# iqn_ail register map
Vendor: Texas Instruments
Registers are 32-bit, read-only, no defined reset value unless marked. A register's access mark holds for its fields unless they carry their own. Offsets are as the file gives them; [hi:lo] are bit positions; lines under a group give offsets from that group; {n}, {i} and the like mark numbered series; 'fields as' and 'values as' point back to an identical list.

## IQN_AIL (part 2 of 5)
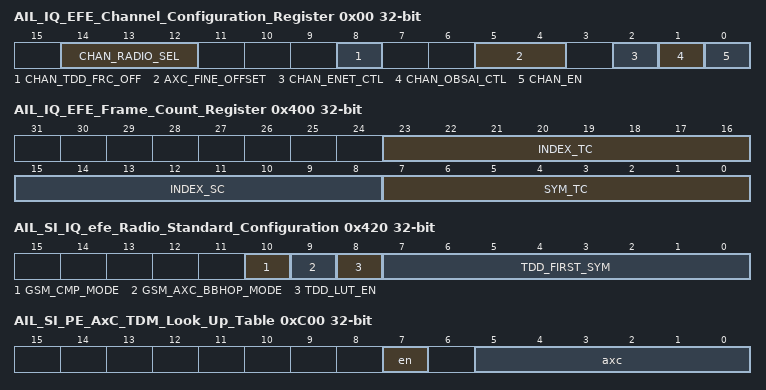
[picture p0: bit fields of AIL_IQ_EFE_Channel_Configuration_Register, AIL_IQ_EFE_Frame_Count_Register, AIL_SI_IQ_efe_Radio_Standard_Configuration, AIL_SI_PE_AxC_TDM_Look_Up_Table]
0x00 AIL_IQ_EFE_Channel_Configuration_Register rw — (1 of 1, stride 0)
  [14:12] CHAN_RADIO_SEL — Assigns each channel to one of eight radio standard groups. i.e. radio standard 0 may be LTE 20MHz
  [8] CHAN_TDD_FRC_OFF — Alternate TDD mode for controlling TDD also used for GSM Base Band Hopping. APP SW controls updates this bit each symbol of time to control whether the next symbol will be TDD OFF. TDD OFF channels generate no Ingress DMA traffic and expect no Egress DMA
  [5:4] AXC_FINE_OFFSET — Selects sample in a QSD that would be the start of the frame.
  [2] CHAN_ENET_CTL — Selects ENET mode when high and non-ENET mode when low.
  [1] CHAN_OBSAI_CTL — Selects when OBSAI CTL traffic is being passed on an SI_IQ channel (CPRI CTL traffic is passed on the SI_CTL). CTL traffic is on-demand while AxC traffic is streaming. Prevents SI_IQ from activating the starvation handling circuits when packet traffic is
  [0] CHAN_EN — Enable channel
0x200 AIL_IQ_EFE_Configuration_Register rw — (1 of 1, stride 0)
  [0] LOOPBACK_EN — (TI use Only) 0x1: Ingress data from ICC is looped back to Egress data to ICC. DMA traffic is unused. (i.e. for purpose of early DFE only testing)
0x240 AIL_IQ_EFE_Global_Enable_Set_Reg wo — (1 of 1, stride 0)
  [31:0] DONT_CARE — A write of any value to this register which sets (enables) global enable
0x244 AIL_IQ_EFE_Global_Enable_Clear_Reg wo — (1 of 1, stride 0)
  [31:0] DONT_CARE — A write of any value to this register which clears (enables) global enable
0x248 AIL_IQ_EFE_Global_Enable_Status — (1 of 1, stride 0)
  [0] ENABLE — 0x1: efe_ON 0x0:efe_OFF
0x260 AIL_IQ_EFE_Channel_ON_Status_Reg — (1 of 1, stride 0)
  [31:0] CHAN_ON — 0x1: CHAN_ON 0x0:CHAN_OFF
0x280 AIL_IQ_EFE_IN_Packet_Status_Registers — (1 of 1, stride 0)
  [31:0] IN_PKT — 0x1: IN_PKT 0x0:OUT_PKT
0x2A0 AIL_IQ_EFE_DMA_SYNC_Status_Registers — (1 of 1, stride 0)
  [31:0] DMA_SYNC — 0x1: DMA synchronized to radio timing for this channel 0x0:DMA not synchronized to radio timing for this channel. Channel is in in re-sync mode.
0x400 AIL_IQ_EFE_Frame_Count_Register rw — (1 of 1, stride 0)
  [23:16] INDEX_TC — Radio Framing Counter. Index Counter Terminal Count. Index counter terminal count which is the last value of the Index Counter before it wraps. For simple use case, program same as frm_sym_tc.
  [15:8] INDEX_SC — Radio Framing Counter. Index Counter Starting Location. Starting location of the Sample Terminal Count LUT loaded into the Index Counter when it first starts and each time it wraps. Depending on the radio standard, the index will wrap once per radio frame
  [7:0] SYM_TC — Radio Framing Counter. Symbol Count. Number of symbols per frame programmed as a terminal count.
0x420 AIL_SI_IQ_efe_Radio_Standard_Configuration rw — (1 of 1, stride 0)
  [10] GSM_CMP_MODE — Enables GSM Compressed mode
  [9] GSM_AXC_BBHOP_MODE — Enables Base-band Hopping mode
  [8] TDD_LUT_EN — Enable TDD
  [7:0] TDD_FIRST_SYM — Selects first symbol to start TDD
{0x440+0x20*i} AIL_IQ_efe_Radio_Standard_{i}_TDD_ENABLE_LUT rw (i=0..7) — (1 of 1, stride 0)
  [31:0] TDD_EN — enables/disables DMA of whole symbols (PktDMA packets). Program as 0xffff for most applications.
0x600 AIL_IQ_EFE_Channel_AXC_Offset_Reg rw — (1 of 64, stride 4)
  [24:0] AXC_OFFSET — AxC-by-AxC delay control. Allows different timing alignments for each AxC. DIO, AID applicactions this is a 4 sample offset relatvie to the group or TDM of AxC. AIL CPRI, this is a sample offset relative to the CPRI AxC Group. AIL OBSAI, this is a Radio
0x800 AIL_IQ_EFE_AxC_Framing_Sample_Terminal_Count rw — (1 of 256, stride 4)
  [17:0] SAMP_TC — Radio Framing Counter. Number of samples (4 Bytes) per radio symbol programmed as a terminal count
0xC00 AIL_SI_PE_AxC_TDM_Look_Up_Table rw — (1 of 256, stride 4)
  [7] en — Enables each entry. Disabled entries will result in zeroed CPRI containers. Main use of this disable, so APP SW is not required to maintain unique AxC value for unused containers.
  [5:0] axc — List of AxC indexes giving TDM AxC order over CPRI or OBSAI link
0x1000 AIL_SI_PE_PHY_Configuration_Register rw — (1 of 1, stride 0)
  [0] phy_en — SI Egress AIL scheduler, PHY FSM is enabled to turn ON, will turn on next PE_FB from uAT
0x1004 AIL_SI_PE_PHY_Status_Register — (1 of 1, stride 0)
  [0] phy_on — SI Egress AIL scheduler, active high, indicating that the PE PHY is in ON state. PE PHY will only turn ON/OFF on PE_FB boundaries.
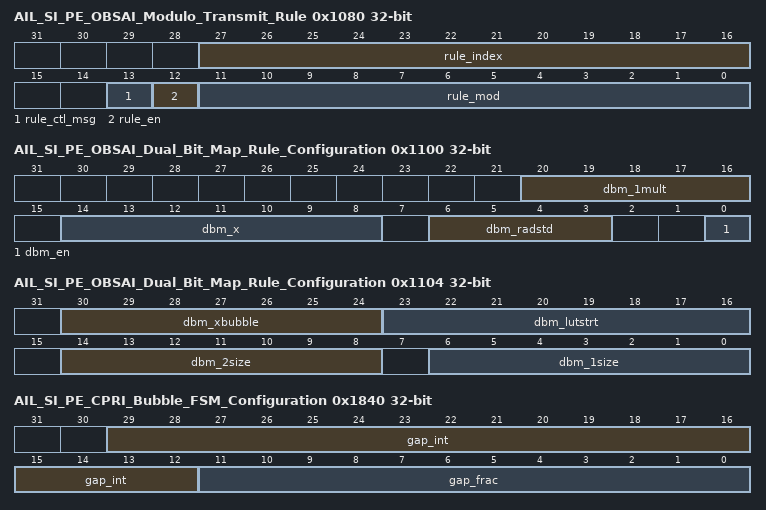
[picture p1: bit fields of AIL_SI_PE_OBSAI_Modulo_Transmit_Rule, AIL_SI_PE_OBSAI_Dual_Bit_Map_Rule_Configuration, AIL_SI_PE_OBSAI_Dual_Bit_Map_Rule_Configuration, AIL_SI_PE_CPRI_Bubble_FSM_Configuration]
0x1080 AIL_SI_PE_OBSAI_Modulo_Transmit_Rule rw — (1 of 1, stride 0)
  [27:16] rule_index — Index. Transmission Rule. Index indicates at which count the rule will fire.
  [13] rule_ctl_msg — 1: Module Rule oppeations on OBSAI control messages 0: AxC messages
  [12] rule_en — Transmission Rule Enable.
  [11:0] rule_mod — Modulo Terminal count of the rule counter. Dictates the period of the rule. Terminal count is the OBSAI Module minus 1.
0x1100 AIL_SI_PE_OBSAI_Dual_Bit_Map_Rule_Configuration rw — (1 of 32, stride 8)
  [20:16] dbm_1mult — DBMF repititions of map1
  [14:8] dbm_x — DBMF max number of supported channels
  [6:3] dbm_radstd — OBSAI only: Radio Standard 0-7 corresponding to the given rule. Controls which RADT to be used flr AxC_Offset comparison. Highly recommended to use a single rule per radio standard to simplify AxC_Offset calculations
  [0] dbm_en — DBMF Enable: When disabled and MOD rule fires, first AxC LUT entry is used and other DBM programming is disregarded
0x1104 AIL_SI_PE_OBSAI_Dual_Bit_Map_Rule_Configuration rw — (1 of 32, stride 8)
  [30:24] dbm_xbubble — Normally programmed to 0 corresponding to 1 bubble when a bubble is indicated by Map1 or Map2 pattern. (Future Proof) feature allows a burst of bubbles to be inserted. Burst length indicated by this MMR
  [23:16] dbm_lutstrt — DBMF Starting address for chan TDM LUT pe_rule_chanlut. LUT is shared by all 32 DBM rules. Starting address indicates where pattern for this rule starts
  [14:8] dbm_2size — DBMF number of bits of bit map2 to use.
  [6:0] dbm_1size — DBMF number of bits of bit map1 to use.
0x1400 AIL_SI_PE_OBSAI_Dual_Bit_Map_Rule__Bit_Map rw — (1 of 256, stride 4)
  [31:0] dbm_bit_map — DBMF bit map 1,2
0x1800 AIL_SI_PE_CPRI_Configuration_Register rw — (1 of 1, stride 0)
  [6:0] axc_cont_tc — CPRI,indicating how many CPRI AxC containers are supported within each basic frame. Value must be consistently programmed with AIL_PHY_Egress programmed values or erroneous operation will result.. Programmed values 0-to-63 correspond to length 1-to-64.
0x1820 AIL_SI_PE_CPRI_Bubble_FSM_Configuration rw — (1 of 1, stride 0)
  [31:14] knc — (K x Nc) total number of containers per AxC Container Block. 0=one
0x1840 AIL_SI_PE_CPRI_Bubble_FSM_Configuration rw — (1 of 1, stride 0)
  [29:12] gap_int — fsm-by-fsm, integer number of containers between bubbles. 0=one which indicates every clock would be a bubble, assuming bub_gap_frac is also zero. Algorithm rewinds at the beginning of each AxC Container Block
  [11:0] gap_frac — fsm-by-fsm, fractional number of containers between bubbles. 0=zero. Value is accumulated every bubble, in this way, a non-zero fraction eventually accumulates into the integer field
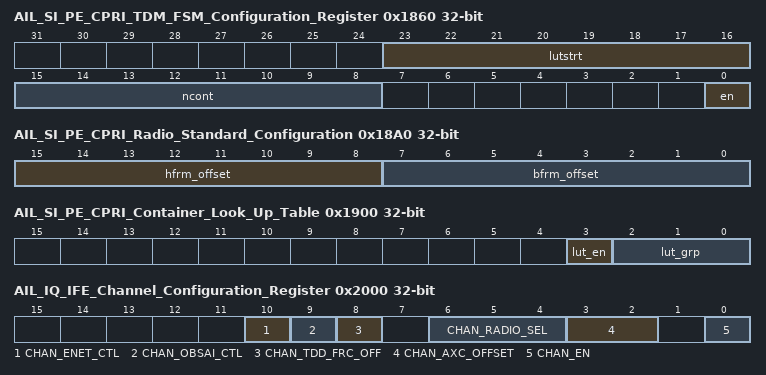
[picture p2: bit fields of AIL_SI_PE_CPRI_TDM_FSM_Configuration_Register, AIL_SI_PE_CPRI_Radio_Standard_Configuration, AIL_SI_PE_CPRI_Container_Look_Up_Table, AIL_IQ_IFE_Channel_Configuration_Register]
0x1860 AIL_SI_PE_CPRI_TDM_FSM_Configuration_Register rw — (1 of 1, stride 0)
  [23:16] lutstrt — first AxC_LUT entry for this fsm. Effectively controls how the table is shared betweeen up to 8 groups or fsm
  [15:8] ncont — number of AxC_LUT entries for this FSM (For each LTE20, 8 sequential entries within AxC_LUT)
  [0] en — FIXME REMOVE THIS MMR FIELD... REDUNDANT WITH pe_cpri_radstd_cfg.en
0x1880 AIL_SI_PE_CPRI_Radio_Standard_Configuration rw — (1 of 1, stride 0)
  [0] en — Enable bit for the corresponding radio standard First enabled radstd must be radstd0, next radstd1, ...
0x18A0 AIL_SI_PE_CPRI_Radio_Standard_Configuration rw — (1 of 1, stride 0)
  [15:8] hfrm_offset — Hyper Frame Index of Radio Standard Offset
  [7:0] bfrm_offset — Basic Frame Index of Radio Standard Offset
0x18C0 AIL_SI_PE_CPRI_Radio_Standard_Configuration rw — (1 of 1, stride 0)
  [17:0] bfrm_num — Number of Basic Frames in a Radio Standard
0x18E0 AIL_SI_PE_CPRI_Radio_Standard_Status_Register — (1 of 1, stride 0)
  [0] on — 0x1: RADSTD_ON 0x0:RADSTD_OFF
0x1900 AIL_SI_PE_CPRI_Container_Look_Up_Table rw — (1 of 1, stride 0)
  [3] lut_en — Enable or Disable of each contain, even if disabled, CONT_LUT_GRP must be programmed correctly
  [2:0] lut_grp — Group (radio standard) which container belongs to, 0-to-7. When programming must exactly match the AIL_PHY_CO programmed pperation.
0x2000 AIL_IQ_IFE_Channel_Configuration_Register rw — (1 of 1, stride 0)
  [10] CHAN_ENET_CTL — Selects between OBSAI ENET when high or OBSAI NON_ENET when low. Only valid when CHAN_OBSAI_CTL is set
  [9] CHAN_OBSAI_CTL — Selects between OBSAI when high or CPRI when low.
  [8] CHAN_TDD_FRC_OFF — Forces a channel into the TDD OFF state on the next symbol after it is set to a 1 regardless of the TDD configuration of the radio standard variant the channel is assigned to.
  [6:4] CHAN_RADIO_SEL — Radio Standard Select
  [3:2] CHAN_AXC_OFFSET — AxC Offset
  [0] CHAN_EN — Enable channel
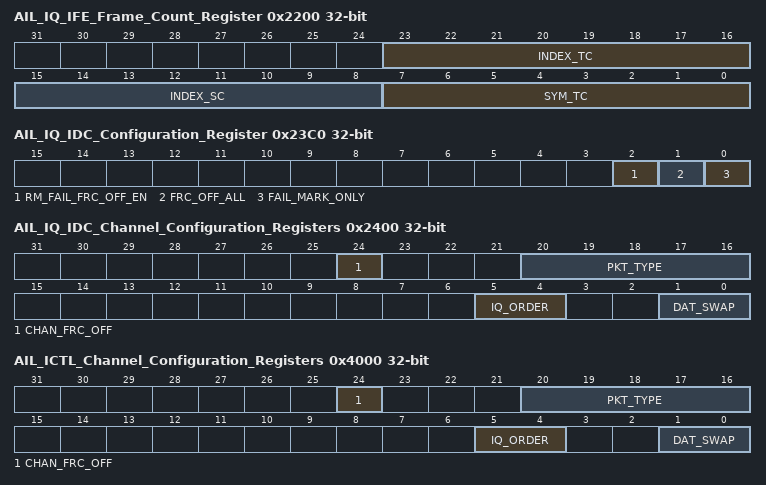
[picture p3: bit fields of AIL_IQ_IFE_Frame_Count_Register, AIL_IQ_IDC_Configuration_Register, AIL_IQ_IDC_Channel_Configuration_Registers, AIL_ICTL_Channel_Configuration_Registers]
0x2200 AIL_IQ_IFE_Frame_Count_Register rw — (1 of 1, stride 0)
  [23:16] INDEX_TC — Radio Framing Counter. Index Counter Terminal Count. Index counter terminal count which is the last value of the Index Counter before it wraps. For simple use case, program same as frm_sym_tc.
  [15:8] INDEX_SC — Radio Framing Counter. Index Counter Starting Location. Starting location of the Sample Terminal Count LUT loaded into the Index Counter when it first starts and each time it wraps.
  [7:0] SYM_TC — Radio Framing Counter. Symbol Count. Number of symbols per frame programmed as a terminal count.
0x2220 AIL_IQ_IFE_Radio_Standard_Configuration rw — (1 of 1, stride 0)
  [0] TDD_LUT_EN — Enable TDD
{0x2240+0x20*i} AIL_IQ_IFE_Radio_Standard_{i}_TDD_ENABLE_LUT rw (i=0..7) — (1 of 1, stride 0)
  fields as AIL_IQ_efe_Radio_Standard_0_TDD_ENABLE_LUT
0x2340 AIL_IQ_IFE_Global_Enable_Set_Reg wo — (1 of 1, stride 0)
  fields as AIL_IQ_EFE_Global_Enable_Set_Reg
0x2344 AIL_IQ_IFE_Global_Enable_Clear_Reg wo — (1 of 1, stride 0)
  fields as AIL_IQ_EFE_Global_Enable_Clear_Reg
0x2348 AIL_IQ_IFE_Global_Enable_Status — (1 of 1, stride 0)
  [0] ENABLE — 0x1: ife_ON 0x0:ife_OFF
0x2350 AIL_IQ_IFE_Channel_ON_Status_Reg — (1 of 1, stride 0)
  [31:0] CHAN_ON — 0x1: CHAN_ON 0x0:CHAN_OFF
0x2360 AIL_IQ_IFE_IN_Packet_Status_Registers — (1 of 1, stride 0)
  [31:0] IN_PKT — 0x1: IN_PKT 0x0:OUT_PKT
0x2384 AIL_IQ_IDC_Status_Register — (1 of 1, stride 0)
  [0] EMPTY — Empty indicator for both the PSI Staging FIFO and the CDC FIFO
0x2390 AIL_IQ_IDC_In_Packet_Status_Register — (1 of 1, stride 0)
  [31:0] INPKT — Per-channel in packet status bits where a 0 indicates that the channel is not actively processing a packet and a 1 indicates that it is actively processing a packet. The inpkt to channel assignment is such that inpkt\[0\] is associated with channel 0 and
0x23C0 AIL_IQ_IDC_Configuration_Register rw — (1 of 1, stride 0)
  [2] RM_FAIL_FRC_OFF_EN — Forces off all Ingress channels without waiting for an end of symbol or time slot if there is an RM failure. All open packets are automatically closed by creating an EOP for each open packet
  [1] FRC_OFF_ALL — Forces off all Ingress channels without waiting for an end of symbol or time slot. All open packets are automatically closed by creating an EOP for each open packet
  [0] FAIL_MARK_ONLY — Controls how the IDC handles packet errors detected by IFE
0x2400 AIL_IQ_IDC_Channel_Configuration_Registers rw — (1 of 1, stride 0)
  [24] CHAN_FRC_OFF — Forces off all channel without waiting for an end of symbol or time slot. If channel has an open packet it is automatically closed by creating an EOP
  [20:16] PKT_TYPE — Programmable packet type that is inserted into pkt_type field of PKTDMA Info Word 0.
  [5:4] IQ_ORDER — IQ swapping control.
  [1:0] DAT_SWAP — Byte swapping control.
0x2800 AIL_IQ_IFE_AxC_Framing_Sample_Terminal_Count rw — (1 of 256, stride 4)
  fields as AIL_IQ_EFE_AxC_Framing_Sample_Terminal_Count
0x3000 AIL_ECTL_Global_Enable_Set_Reg wo — (1 of 1, stride 0)
  fields as AIL_IQ_EFE_Global_Enable_Set_Reg
0x3004 AIL_ECTL_Global_Enable_Clear_Reg wo — (1 of 1, stride 0)
  fields as AIL_IQ_EFE_Global_Enable_Clear_Reg
0x3008 AIL_ECTL_Global_Enable_Status — (1 of 1, stride 0)
  [0] ENABLE — 0x1: ectl_ON 0x0:ectl_OFF
0x3100 AIL_ECTL_Channel_ON_Status_Reg — (1 of 1, stride 0)
  [3:0] CHAN_ON — 0x1: CHAN_ON 0x0:CHAN_OFF
0x3140 AIL_ECTL_In_Packet_Status_Register — (1 of 1, stride 0)
  [3:0] IN_PKT — Per-channel in packet status bits where a 0 indicates that the channel is not actively processing a packet and a 1 indicates that it is actively processing a packet. The inpkt to channel assignment is such that inpkt\[0\] is associated with channel 0 and
0x3200 AIL_ECTL_Channel_Enable_Configuration_Register rw — (1 of 1, stride 0)
  [0] CHAN_EN — Enable channel
0x3400 AIL_ECTL_DB_Threshold_Register rw — (1 of 1, stride 0)
  [4:0] CHANNEL — Data Buffer Threshold before indicating data available. Per channel
0x4000 AIL_ICTL_Channel_Configuration_Registers rw — (1 of 1, stride 0)
  [24] CHAN_FRC_OFF — Forces off all channel without waiting for an EOP. If channel has an open packet it is automatically closed by creating an EOP
  [20:16] PKT_TYPE — Programmable packet type that is inserted into pkt_type field of PKTDMA Info Word 0.
  [5:4] IQ_ORDER — IQ swapping control.
  [1:0] DAT_SWAP — Byte swapping control.
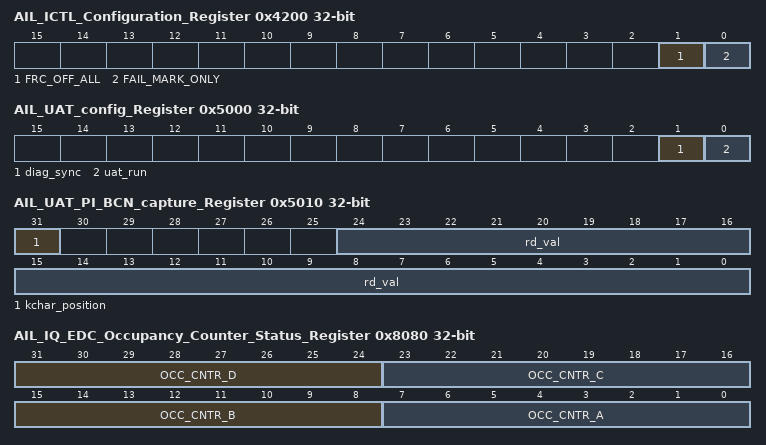
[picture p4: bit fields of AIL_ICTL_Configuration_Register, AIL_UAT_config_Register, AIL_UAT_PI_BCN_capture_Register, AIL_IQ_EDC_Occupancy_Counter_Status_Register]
0x4200 AIL_ICTL_Configuration_Register rw — (1 of 1, stride 0)
  [1] FRC_OFF_ALL — Forces off all Ingress channels without waiting for an EOP. All open packets are automatically closed by creating an EOP for each open packet
  [0] FAIL_MARK_ONLY — Controls how the ICTL handles packet errors detected by ICTL
0x4204 AIL_ICTL_Status_Register — (1 of 1, stride 0)
  fields as AIL_IQ_IDC_Status_Register
0x4210 AIL_ICTL_In_Packet_Status_Register — (1 of 1, stride 0)
  fields as AIL_ECTL_In_Packet_Status_Register
0x4280 AIL_ICTL_Global_Enable_Set_Reg wo — (1 of 1, stride 0)
  fields as AIL_IQ_EFE_Global_Enable_Set_Reg
0x4284 AIL_ICTL_Global_Enable_Clear_Reg wo — (1 of 1, stride 0)
  fields as AIL_IQ_EFE_Global_Enable_Clear_Reg
0x4288 AIL_ICTL_Global_Enable_Status — (1 of 1, stride 0)
  [0] ENABLE — 0x1: ictl_ON 0x0:ictl_OFF
0x42A0 AIL_ICTL_Channel_ON_Status_Reg — (1 of 1, stride 0)
  [3:0] CHAN_ON — 0x1: CHAN_ON 0x0:CHAN_OFF
0x4400 AIL_ICTL_Channel_Enable_Configuration_Register rw — (1 of 1, stride 0)
  [0] CHAN_EN — Enable channel
0x5000 AIL_UAT_config_Register rw — (1 of 1, stride 0)
  [1] diag_sync — diag_sync = 1 starts the BCN and RAD counters if uat_run is set and an AT sync is received. This is only used in simulation and for diagnostics
  [0] uat_run — UAT run starts the BCN and RAD counters free running
0x5004 AIL_UAT_BCN_terminal_count_Register rw — (1 of 1, stride 0)
  [24:0] val — UAT BCN terminal count. BCN counts from zero to this limit and wraps to zero. Program as 2,457,599 for sys_clk=245.76MHz and 3,071,999 for sys_clk=307.2MHz
0x5008 AIL_UAT_BCN_offset_Register rw — (1 of 1, stride 0)
  [24:0] val — Offset correction to the raw uAT BCN counter. Used to correct the alignment of the local uAT BCN to the master AT2 BCN. BCN is initially randomly started. SW uses uat_sync_bcn_capture_sts rd_val to calculate offset correction factor. This correction
0x500C AIL_UAT_SYNC_BCN_capture_Register — (1 of 1, stride 0)
  [24:0] rd_val — uAT raw BCN value captured each frame boundary of AT2 master BCN. Used to calculate uAT BCN offset value for the purpose of aligning uAT to AT2 BCN.
0x5010 AIL_UAT_PI_BCN_capture_Register — (1 of 1, stride 0)
  [31] kchar_position — (AIL use only) uAT pi K character position. Captures the k character position when the AIL_PHY_RM detects a CPRI or OBSAI PHY frame boundary (SOF). 0 means that the kchar for SOF was detected on the lower byte of the SERDES receive data, 1 means upper
  [24:0] rd_val — (AIL use only) uAT pi BCN capture. Captures the BCN timer value when the AIL_PHY_RM detects a CPRI or OBSAI PHY frame boundary (SOF).
0x5014 AIL_UAT_PIMAX_CFG rw — (1 of 1, stride 0)
  [24:0] val — (AIL use only) PI max window. One of two values which indicate the legal range for OBSAI or CPRI PHY SOF. When an SOF is recieved outside this window, and error is indicated (EE)
0x5018 AIL_UAT_PIMIN_CFG rw — (1 of 1, stride 0)
  [24:0] val — (AIL use only) PI min window. One of two values which indicate the legal range for OBSAI or CPRI PHY SOF. When an SOF is recieved outside this window, and error is indicated (EE)
0x501C AIL_UAT_RP301_BCN_capture_Register — (1 of 1, stride 0)
  [24:0] rd_val — (AIL use only) uAT RP3-01 BCN capture. Captures the BCN offset count when the phy detects an OBSAI RP3-01 strobe from the AIL_PD.
0x5020 AIL_UAT_TM_Frame_configuration_Register wo — (1 of 1, stride 0)
  [11:0] wr_val — (AIL CPRI use only) uAT CPRI BFN count value (Write only). SW overwrite current value. uAT will increment every TM_FRM_STB
0x5024 AIL_UAT_TM_Frame_status_Register — (1 of 1, stride 0)
  [11:0] rd_val — (AIL CPRI use only) uAT CPRI BFN count value (Read only). Initially set by uat_tm_bfn_cfg, increments every CPRI PHY frame.
0x5028 AIL_UAT_RT_FB_Register rw — (1 of 1, stride 0)
  [24:0] val — (AIL use only) uAT BCN compare value which cause RT_STB to fire. Used for Egress PHY timing. RT_STB is the latest moment that RT will wait for PE and CI SOF contribution before progressing without either input.
0x502C AIL_UAT_pe_FB_Register rw — (1 of 1, stride 0)
  [24:0] val — (AIL use only) uAT BCN compare value which cause PE_STB to fire. Used for Egress PROTO, PHY timing. PE_STB is the exact time which PE will start building the PHY protocol. It also represents the latest timing for incoming DMA data to contribute to the
0x5030 AIL_UAT_tm_FB_Register rw — (1 of 1, stride 0)
  [24:0] val — (AIL use only) uAT BCN compare value which cause RT_STB to fire. Used for Egress PHY timing. TM_STB (OBSAI Delta) is the precise time at which TM exports the CPRI or OBSAI PHY SOF
0x5080 AIL_UAT_RADT_terminal_count_Register rw — (1 of 8, stride 16)
  [24:0] val — UAT RADT terminal count. (i.e. 2,457,599 for WCDMA with sys_clk=245.76MHz)
0x5084 AIL_UAT_RADT_offset_Register rw — (1 of 8, stride 16)
  [24:0] val — UAT RADT offset. Value which is added to the raw RADT as a timing correction. RadT is initially randomly started, SW uses radt_capture value to calculate offset correction factor. This correction factor will be Frame size
0x5088 AIL_UAT_SYNC_RADT_capture_Register — (1 of 8, stride 16)
  [24:0] rd_val — UAT RADT sync capture captures the offset RADT count when a uat_mst_slv_sync from the AT occurs. Used by SW to determine correct RADT offset to apply.
0x5100 AIL_UAT_RADT_terminal_count_Register rw — (1 of 8, stride 16)
  fields as AIL_UAT_RADT_terminal_count_Register
0x5104 AIL_UAT_RADT_offset_Register rw — (1 of 8, stride 16)
  fields as AIL_UAT_RADT_offset_Register
0x5108 AIL_UAT_SYNC_RADT_capture_Register — (1 of 8, stride 16)
  fields as AIL_UAT_SYNC_RADT_capture_Register
0x5200 AIL_UAT_RADT_event_compare_Register rw — (1 of 22, stride 8)
  [24:0] val — UAT RADT event compare per RADT. When compare value equals RADT count, frame rate event is generated. Also periodic event (i.e. 4SAMP) is started. The 0 to 7 are for si egress, 8 to 15 for si ingress, 16 to 18 for dio egress, 19 to 21 for dio ingress
0x5204 AIL_UAT_RADT_event_clock_count_tc_Register rw — (1 of 22, stride 8)
  [15:0] val — UAT RADT event clock counter terminal count controls spacing of the periodic strobe (i.e. 4SAMP). Once the uat_evt_radt_cmp_cfg equals the RADT, the period strobe will fire and re-fire every time a clock counter reaches this terminal count. The The 0 to 7
0x8000 AIL_IQ_EDC_Configuration_Register rw — (1 of 1, stride 0)
  [0] PSI_ERR_CHK_DISABLE — Controls how the EDC handles packet errors detected by efe
0x8004 AIL_IQ_EDC_SOP_Counter_Status_Register — (1 of 1, stride 0)
  [23:0] SOP_CNT — Count of the number of SOPs seen by the IQ EDC
0x8008 AIL_IQ_EDC_EOP_Counter_Status_Register — (1 of 1, stride 0)
  [23:0] EOP_CNT — Count of the number of EOPs seen by the IQ EDC
0x8080 AIL_IQ_EDC_Occupancy_Counter_Status_Register — (1 of 1, stride 0)
  [31:24] OCC_CNTR_D — Occupancy Counter for register D for this address
  [23:16] OCC_CNTR_C — Occupancy Counter for register C for this address
  [15:8] OCC_CNTR_B — Occupancy Counter for register B for this address
  [7:0] OCC_CNTR_A — Occupancy Counter for register A for this address
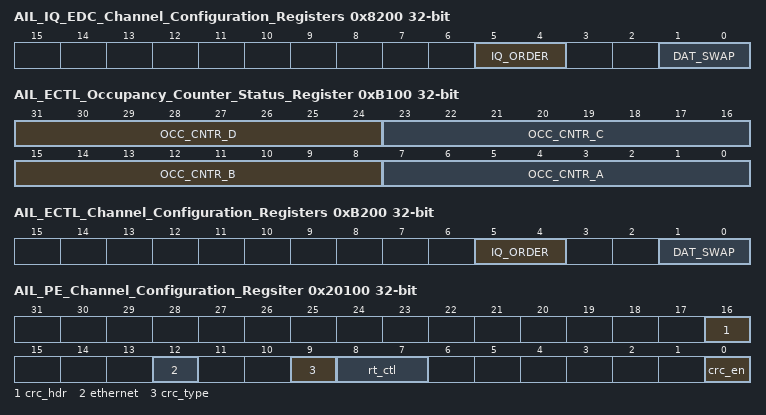
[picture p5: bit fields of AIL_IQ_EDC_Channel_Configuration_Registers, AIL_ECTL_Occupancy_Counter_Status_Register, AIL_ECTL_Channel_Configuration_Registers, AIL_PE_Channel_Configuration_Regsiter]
0x8200 AIL_IQ_EDC_Channel_Configuration_Registers rw — (1 of 1, stride 0)
  [5:4] IQ_ORDER — IQ swapping control.
  [1:0] DAT_SWAP — Byte swapping control.
0xA000 AIL_IQ_IDC_Rate_Control_Configuration_Register rw — (1 of 1, stride 0)
  [3:0] RATE — Rate Controller will allow the IDC to create RATE+1 active requests on the PSI bus within a 32 clock cycle window. As an example, a value of 7 will allow the IDC to create 8 active requests within a 32-clock cycle window which uses 25% of the PSI bus.
0xA004 AIL_IQ_IDC_SOP_Counter_Register — (1 of 1, stride 0)
  [23:0] SOP_CNT — Wrapping count of SOPs sent on PSI.
0xA008 AIL_IQ_IDC_EOP_Counter_Register — (1 of 1, stride 0)
  [23:0] EOP_CNT — Wrapping count of EOPs sent on PSI.
0xB000 AIL_ECTL_Rate_Control_Configuration_Register rw — (1 of 1, stride 0)
  [3:0] RATE — Rate Controller will allow the ECTL to create RATE+1 active requests on the PSI bus within a 16 clock cycle window. As an example, a value of 7 will allow the ICTL to create 8 active requests within a 16-clock cycle window which uses 50% of the PSI bus.
0xB004 AIL_ECTL_SOP_Counter_Status_Register — (1 of 1, stride 0)
  [23:0] SOP_CNT — Count of the number of SOPs seen by the ECTL
0xB008 AIL_ECTL_EOP_Counter_Status_Register — (1 of 1, stride 0)
  [23:0] EOP_CNT — Count of the number of EOPs seen by the ECTL
0xB100 AIL_ECTL_Occupancy_Counter_Status_Register — (1 of 1, stride 0)
  fields as AIL_IQ_EDC_Occupancy_Counter_Status_Register
0xB200 AIL_ECTL_Channel_Configuration_Registers rw — (1 of 1, stride 0)
  fields as AIL_IQ_EDC_Channel_Configuration_Registers
0xC000 AIL_ICTL_Rate_Control_Configuration_Register rw — (1 of 1, stride 0)
  [3:0] RATE — Rate Controller will allow the ICTL to create RATE+1 active requests on the PSI bus within a 16 clock cycle window. As an example, a value of 7 will allow the ICTL to create 8 active requests within a 16-clock cycle window which uses 50% of the PSI bus.
0xC004 AIL_ICTL_SOP_Counter_Register — (1 of 1, stride 0)
  [23:0] SOP_CNT — Wrapping count of SOPs sent on PSI.
0xC008 AIL_ICTL_EOP_Counter_Register — (1 of 1, stride 0)
  [23:0] EOP_CNT — Wrapping count of EOPs sent on PSI.
0x20000 AIL_PE_Global_Configuration_Register rw — (1 of 1, stride 0)
  [8] enet_hdr_sel — when using Ethernet, bit order for Ethernet preamble and SOF 0: 0xAAAAAAAB 1: 0x555555D5
0x20100 AIL_PE_Channel_Configuration_Regsiter rw — (1 of 1, stride 0)
  [16] crc_hdr — OBSAI CRC16 is calculated over OBSAI header as well as payload (only valid for OBSAI TYPES CONTROL (0x0) and MEASUREMENT (0x1)
  [12] ethernet — OBSAI Channel is ethernet. This field controls insertion of the Ethernet Praemble and SOF (and prevents CRC of these bytes)
  [9] crc_type — OBSAI CRC: length of CRC
  [8:7] rt_ctl — OBSAI/CPRI Controls RT to perform appropriate insertion/aggregation into PHY applied on msg-by-msg basis for OBSAI or sample-by-sample basis for CPRI
  [0] crc_en — CRC: enable CRC generation and insert on AxC by AxC basis
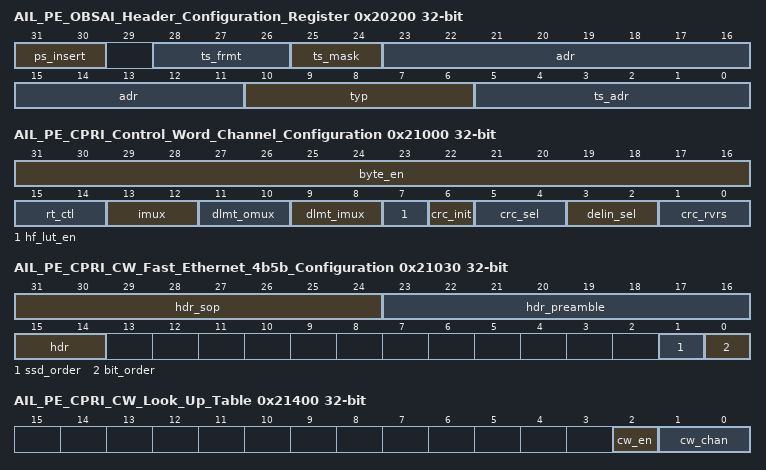
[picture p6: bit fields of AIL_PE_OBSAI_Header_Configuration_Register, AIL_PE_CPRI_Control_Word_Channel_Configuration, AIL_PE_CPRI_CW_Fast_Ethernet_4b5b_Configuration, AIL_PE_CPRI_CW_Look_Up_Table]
0x20200 AIL_PE_OBSAI_Header_Configuration_Register rw — (1 of 64, stride 4)
  [31:30] ps_insert — Normal header processing is performed except the above MMR adr, type, ts_adr fields are unsed and instead this information is replaced with the CPPI DMA protocol specific (ps) data. Effectively, when used, ps data allows APP SW to control OBSAI header on
  [28:26] ts_frmt — TS: OBSAI time stamp generation algorithm
  [25:24] ts_mask — Controls which parts of the OBSAI TS field are inserted vs. calculated
  [23:11] adr — OBSAI hdr(23:11)ADR : inserted into OBSAI header ADDRESS field
  [10:6] typ — OBSAI hdr(10:6) TYPE: inserted into OBSAI header TYPE field
  [5:0] ts_adr — OBSAI hdr( 5:0) TS : only used if TS is inserted instead of generated
0x21000 AIL_PE_CPRI_Control_Word_Channel_Configuration rw — (1 of 1, stride 2048)
  [31:16] byte_en — CW byte Enable, used to disable CW bytes for some low rate HDLC or 5x/10x RTWP. (normal set to 0xffff)
  [15:14] rt_ctl — Controls AIL_PHY_RT to perform appropriate insertion/aggregation into PHY, applied on sample by sample basis.
  [13:12] imux — CW circuit input swapper (Nibble or bits within each byte). Before CRC calcuation and before Delim, effects both CRC result and effects input to Delim circuit.
  [11:10] dlmt_omux — Delim Circuit output swapper mux (Nibble or bits within each byte). After CRC operation, after Delim operation
  [9:8] dlmt_imux — Delim Circuit input swapper mux (Nibble or bits within each byte). After CRC operation, Before Delim operation
  [7] hf_lut_en — Enable use of hyperframe_lut (which limits usable hyperframes), intended use is RTWP (normally not used)
  [6] crc_init — Selects if the CRC starts with a value of 0 or
  [5:4] crc_sel — Select which form of CRC generation and insertion to perform
  [3:2] delin_sel — Select which form of delineation is to be used for this chan
  [1:0] crc_rvrs — 0: normal no byte reversal for CRC, 1: reverse crc16 byte order (illegal for CRC8 or CRC32)
{0x21010+4i} AIL_PE_CPRI_CW_Hyperframe_Look_Up_Table_Part{i} rw (i=0..3) — (1 of 1, stride 2048)
  [31:0] hf_en — Enable bit per Hyperframe, 1: hyperframe used, 0: hyperframe unused
0x21020 AIL_PE_CPRI_CW_Hyperframe_Look_Up_Table_Part4 rw — (1 of 1, stride 2048)
  [21:0] hf_en — Enable bit per Hyperframe, 1: hyperframe used, 0: hyperframe unused
0x21024 AIL_PE_CPRI_CW_Null_Character_Configuration rw — (1 of 1, stride 2048)
  [8:0] null_char — Null Delineator Character: bit8 indicates k_char
0x21028 AIL_PE_CPRI_CW_CRC8_Configuration_Register rw — (1 of 1, stride 2048)
  [7:0] crc8_poly — CRC8 programmable polynomial
0x2102C AIL_PE_CPRI_CW_Status_Register — (1 of 1, stride 2048)
  [3:0] in_pkt — Each bit indicates if the corresponding channel is active or not. A 1 indicates the channel is currently in the middle of a packet. A 0 indicatest the channel is out of packet
0x21030 AIL_PE_CPRI_CW_Fast_Ethernet_4b5b_Configuration rw — (1 of 1, stride 2048)
  [31:24] hdr_sop — Ethernet header byte to send as the last byte of the preamble (program as 0xD5)
  [23:16] hdr_preamble — Ethernet header byte to send as the first 6 or 7 bytes of the preamble (program as 0x55)
  [15:14] hdr — Selects the number of bytes of the preamble added between the SSD and ESD and the first byte of data.
  [1] ssd_order — Swaps the order of the 2 SSD and ESD 5 bit values when high
  [0] bit_order — Reverses the bit order of the 5 bit 4b5b data when high.
0x21400 AIL_PE_CPRI_CW_Look_Up_Table rw — (1 of 1, stride 2048)
  [2] cw_en — All possible CPRI sub-channel. Dictates whether the control word should be captured at all
  [1:0] cw_chan — Selects which of the 4 channels to use for this basic frame if the enable bit is set
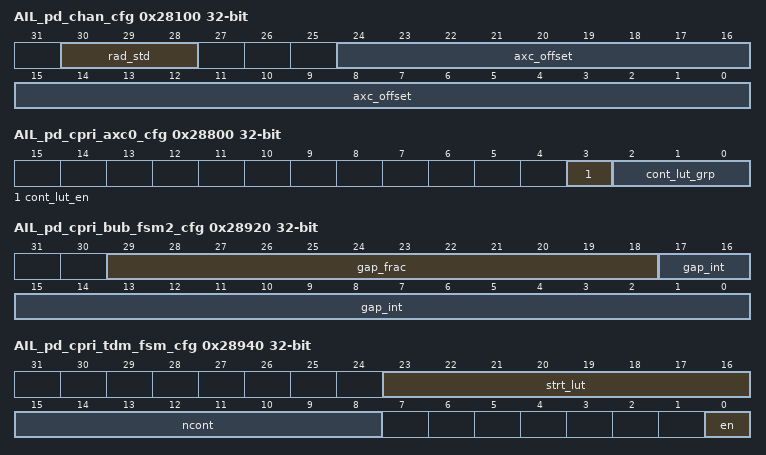
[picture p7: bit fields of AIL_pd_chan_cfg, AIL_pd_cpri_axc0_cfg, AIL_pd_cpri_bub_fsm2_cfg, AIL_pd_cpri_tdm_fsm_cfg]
0x28100 AIL_pd_chan_cfg rw — (1 of 64, stride 4)
  [30:28] rad_std — assign each channel to one of 8 radio standards. Used for radio standard FSM and RadT selection
  [24:0] axc_offset — OBSAI: Antenna Carrier offset programmed in 307.2MHz clocks and relative to the Frame Boundary of the RadT AT timer. Specifies the center of the receive window for an AxC offset (typical WCDMA value of (4chip_offset x 320) + 320/2) CPRI: Antenna Carrier
0x28800 AIL_pd_cpri_axc0_cfg rw — (1 of 1, stride 0)
  [3] cont_lut_en — 0: container is unused by PD 1: container is mapped by cont_lut_grp
  [2:0] cont_lut_grp — Group (radio standard) which container belongs to, 0-to-7. The PD double buffers these registers on every phy frame boundary
0x28900 AIL_pd_cpri_bub_fsm_cfg rw — (1 of 1, stride 0)
  [17:0] knc — (K x Nc) total number of containers per AxC Container Group. 0=one
0x28920 AIL_pd_cpri_bub_fsm2_cfg rw — (1 of 1, stride 0)
  [29:18] gap_frac — Bubble Gap Fractional portion configuration
  [17:0] gap_int — Bubble Gap Integer portion configuration
0x28940 AIL_pd_cpri_tdm_fsm_cfg rw — (1 of 1, stride 0)
  [23:16] strt_lut — first AxC_LUT entry for this fsm.
  [15:8] ncont — number of AxC_LUT entries (containers) for this FSM (For LTE20, 8 sequential entries within AxC_LUT)
  [0] en — enable the FSM. Containers targeting a disabled TDM_FSM are discarded.
0x28960 AIL_pd_cpri_radstd_cfg rw — (1 of 1, stride 0)
  [0] en — Enable bit for the corresponding radio standard
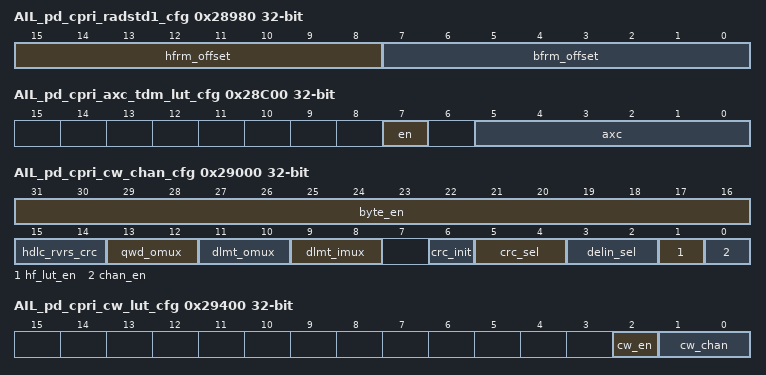
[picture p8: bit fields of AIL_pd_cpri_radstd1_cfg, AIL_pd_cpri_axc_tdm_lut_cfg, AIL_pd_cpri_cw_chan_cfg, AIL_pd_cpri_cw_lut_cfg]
0x28980 AIL_pd_cpri_radstd1_cfg rw — (1 of 1, stride 0)
  [15:8] hfrm_offset — Hyper Frame Index of Radio Standard Offset
  [7:0] bfrm_offset — Basic Frame Index of Radio Standard Offset
0x289A0 AIL_pd_cpri_radstd2_cfg rw — (1 of 1, stride 0)
  [17:0] bfrm_num — Number of Basic Frames in a Radio Standard
0x289C0 AIL_pd_cpri_radstd_sts — (1 of 1, stride 0)
  [0] on — 0x1: RADSTD_ON 0x0:RADSTD_OFF
0x28C00 AIL_pd_cpri_axc_tdm_lut_cfg rw — (1 of 256, stride 4)
  [7] en — Enables each entry. Disabled entries will result in dropped CPRI containers. Main use of this disable is so SW is not required to maintain unique AxC value for unused containers.
  [5:0] axc — List of AxC indexes giving TDM AxC order over CPRI link
0x29000 AIL_pd_cpri_cw_chan_cfg rw — (1 of 1, stride 0)
  [31:16] byte_en — CW byte Enable, used to disable CW bytes for some low rate HDLC or 5x/10x RTWP. (normal use set 0xffff)
  [15:14] hdlc_rvrs_crc — Controls bit swapping of the CRC for the HDLC only
  [13:12] qwd_omux — Final swapping after the CRC operation.
  [11:10] dlmt_omux — Delim Circuit output swapper mux (Nibble or bits within each byte). After Delim operation, before CRC operation
  [9:8] dlmt_imux — Delim Circuit input swapper mux (Nibble or bits within each byte). Before CRC and Delim operation.
  [6] crc_init — Selects if the CRC starts with a value of 0 or
  [5:4] crc_sel — Select which form of CRC check to perform
  [3:2] delin_sel — Select which form of delineation is to be used for this channel
  [1] hf_lut_en — Enables use of hyperframe_lut (which limits usable hyperframes), intended use is RTWP
  [0] chan_en — All possible CPRI sub-channels are are mapped to one of four CPRI CW staging areas. This allow CPRI CW to be split into 4 different streams.
0x29400 AIL_pd_cpri_cw_lut_cfg rw — (1 of 1, stride 0)
  [2] cw_en — All possible CPRI sub-channel. Dictates whether the control word should be captured at all
  [1:0] cw_chan — Selects which of the 4 channels to use for this basic frame if the enable bit is set.
{0x29800+4i} AIL_pd_cpri_hypfrm{i}_lut_cfg rw (i=0..3) — (1 of 1, stride 0)
  fields as AIL_PE_CPRI_CW_Hyperframe_Look_Up_Table_Part0
0x29810 AIL_pd_cpri_hypfrm4_lut_cfg rw — (1 of 1, stride 0)
  fields as AIL_PE_CPRI_CW_Hyperframe_Look_Up_Table_Part4
0x29814 AIL_pd_cpri_null_cfg rw — (1 of 1, stride 0)
  [8:0] null_char — Null Delineator Character: bit8 indicates this is a k_char when set
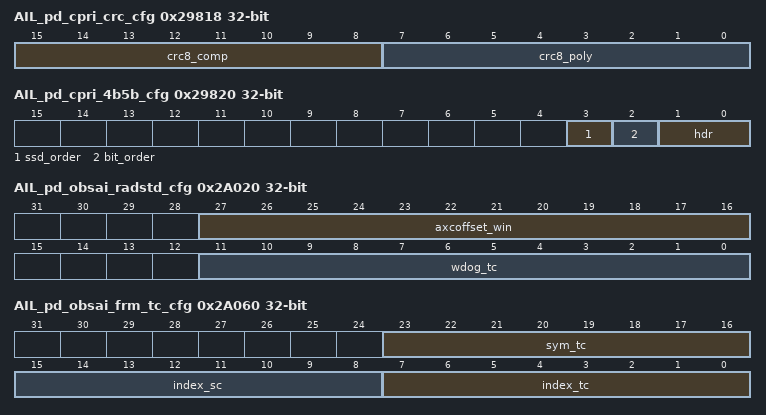
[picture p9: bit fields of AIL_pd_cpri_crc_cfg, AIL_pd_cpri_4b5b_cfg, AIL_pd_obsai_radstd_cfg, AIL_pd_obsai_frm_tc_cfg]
0x29818 AIL_pd_cpri_crc_cfg rw — (1 of 1, stride 0)
  [15:8] crc8_comp — CRC8 compare value when init is choosen as 1's. Sometimes referred as the Magic Number. Depends on chosen polynomial.
  [7:0] crc8_poly — CRC8 programmable polynomial
0x29820 AIL_pd_cpri_4b5b_cfg rw — (1 of 1, stride 0)
  [3] ssd_order — Swaps the order of the 2 SSD and ESD 5 bit values when high. Should always be set low.
  [2] bit_order — Reverses the bit order of the 5 bit 4b5b data when high. Should always be set high.
  [1:0] hdr — Header stripping control selects how many bytes if any to ignore at the start of the packet.
0x2A000 AIL_pd_obsai_gsm_bbhop_cfg wo — (1 of 1, stride 0)
  [31:0] off_stb — 1: next GSM time slot is OFF for this chan 0: normal, expect data to arrive on PHy (Only used if pd_chan_cfg.gsm_bbhop=1)
0x2A010 AIL_pd_obsai_rp3_01_sts — (1 of 1, stride 0)
  [31:0] capture — one of four payload wd
0x2A020 AIL_pd_obsai_radstd_cfg rw — (1 of 1, stride 0)
  [27:16] axcoffset_win — OBSAI reception timing window width parameter. Indicates the window size for searching the radio frame boundary identified by TS=0. Minimum WCDMA value is (320/2 + 80)
  [11:0] wdog_tc — watch dog timer terminal count (sys_clks). Each WDog TC increments WDG 8 count by 1.
0x2A040 AIL_pd_obsai_radt_cfg rw — (1 of 1, stride 0)
  [24:0] tc — Max expected value for the RadT timer value. Used for creating an expected timing window (for which TS=0 marks a Radio Frame Boundary)
0x2A060 AIL_pd_obsai_frm_tc_cfg rw — (1 of 1, stride 0)
  [23:16] sym_tc — Radio framing counter. Symbol terminal count.
  [15:8] index_sc — Radio framing counter. Index Start count.
  [7:0] index_tc — Radio framing counter. Index Terminal count.
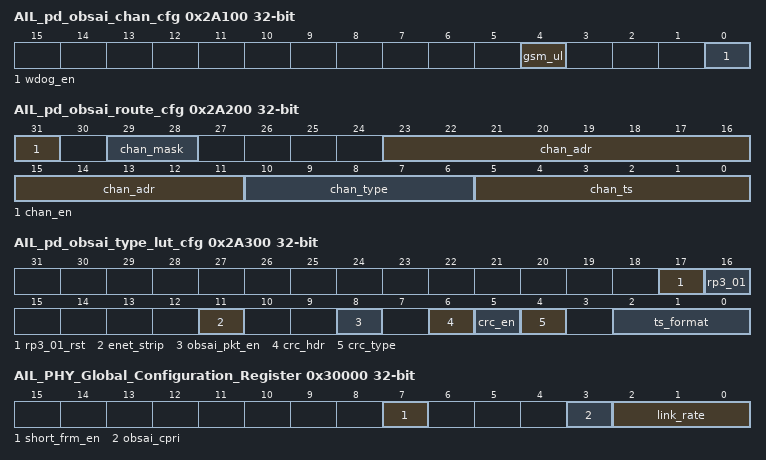
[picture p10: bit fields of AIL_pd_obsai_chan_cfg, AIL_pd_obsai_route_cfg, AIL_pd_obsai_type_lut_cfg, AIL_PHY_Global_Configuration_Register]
0x2A100 AIL_pd_obsai_chan_cfg rw — (1 of 1, stride 0)
  [4] gsm_ul — Data Format
  [0] wdog_en — Enable WDog timer. Used for missing traffic handling and GSM BB_Hop missing EOP. WDog is configured per radstd
0x2A200 AIL_pd_obsai_route_cfg rw — (1 of 1, stride 0)
  [31] chan_en — 0: this channel is always OFF regardless of compare (assumes other fields are junk) 1: channel is enabled
  [29:28] chan_mask — Reception Routing: controls how many OBSAI time stamp bits to use in the reception routing
  [23:11] chan_adr — Reception Routing: OBSAI address
  [10:6] chan_type — Reception Routing: OBSAI type
  [5:0] chan_ts — Reception Routing: OBSAI time stamp. Used to extend addressing by using the TS field. (Only known use is for OBSAI Generic Packet type and Control Packet type) The number of bits of TS to compare is controlled via the mask field.
0x2A300 AIL_pd_obsai_type_lut_cfg rw — (1 of 1, stride 0)
  [17] rp3_01_rst — Used for RP3-01 Reset reception. If message type is received with correct address, the pd_soc_rst signal is set, causing an soc reset, if enabled.
  [16] rp3_01 — Used for RP3-01 FCB reception (slave timing sync via OBSAI link). Capture the OBSAI payload to an MMR, Fire off a strobe to uAT for BCN capture, fire off an EE for purposes of alerting processors of FCB arival
  [11] enet_strip — 0x0: No Strip 0x1: Strip off the first 8 bytes of each packet. Purpose is to strip the ethernet preamble and SOP. PD blindly strips without checking content of 8 bytes. CRC is not calculated over stripped bytes.
  [8] obsai_pkt_en — determines if channel is packet type channel or axc type channel. AxC types align to Radio Frame Boundary while pkt alignment is a don't care. AXC channels are expected to stream where packet channels are on-demand. AXC channels use OBSAI Time Stamp and
  [6] crc_hdr — CRC16 is calculated over OBSAI header as well as payload (only valid for OBSAI TYPES CONTROL (0x0) and MEASUREMENT (0x1)
  [5] crc_en — CRC: enable CRC check on type-by-type basis.
  [4] crc_type — CRC: length of CRC.
  [2:0] ts_format — TS: OBSAI time stamp check (n/a CPRI)
0x2A400 AIL_pd_obsai_frm_msg_tc_cfg rw — (1 of 256, stride 4)
  [15:0] tc — Radio AxC framing counter. nx4 sample count (OBSAI equal to message count). Note this differs from similar registers in the SI_ING and SI_EGR which is programmed in units of samples vs. nx4 samples. For nornal TimeStamp prediction, RadStd FSM does not
0x30000 AIL_PHY_Global_Configuration_Register rw — (1 of 1, stride 0)
  [7] short_frm_en — Short Frame Enable
  [3] obsai_cpri — The OBSAI/CPRI bit defines the mode of operation for the link. This field may only be modified while the AIL is idle and may not be updated on-the-fly
  [2:0] link_rate — The link rate field defines the rate of the link. The field should only be updated if the TM Enable and RM Enable bits are 0. These link rates control the protocl layer as well (PD and PE). The field can be programmed for the following rates
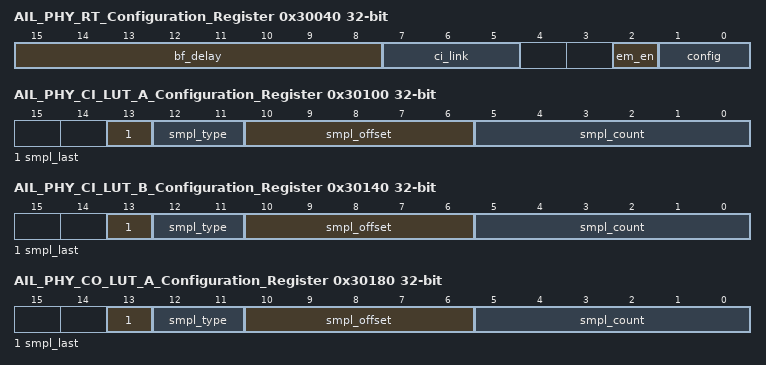
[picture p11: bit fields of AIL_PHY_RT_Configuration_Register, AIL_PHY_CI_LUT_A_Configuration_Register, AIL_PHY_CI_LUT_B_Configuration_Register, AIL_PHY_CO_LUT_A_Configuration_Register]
0x30040 AIL_PHY_RT_Configuration_Register rw — (1 of 1, stride 0)
  [15:8] bf_delay — (CPRI Only) Indicates repositioning of ingress AxC traffic into egress link due to RE Uplin Chaining. This value is the basic frame number on the egress link corresponding to basic frame 0 on the ingress link.
  [7:5] ci_link — Selects which Ingress link is used (forwarding or aggregation) into egress link.
  [2] em_en — (OBSAI Only) Ingress messages are converted to OBSAI Empty Msg when an LCV error is detected in the header. (recommended)
  [1:0] config — The RT Config field defines the operation mode of the RT Block
0x30044 AIL_PHY_RT_Depth_Status_Register — (1 of 1, stride 0)
  [8:0] value — The RT Depth status displays the operating depth of the RT link buffer
0x30048 AIL_PHY_RT_Header_Error_Status_Register — (1 of 1, stride 0)
  [5:0] chan — The RT Header Error status bits indicate the DMA channel of the message that the header error occurred
0x30080 AIL_PHY_CI_LUT_Select_Configuration_Register rw — (1 of 1, stride 0)
  [0] sel — 0 Selects Table A, 1 Selects Table B
0x300C0 AIL_PHY_CO_LUT_Select_Configuration_Register rw — (1 of 1, stride 0)
  [0] sel — 0 Selects Table A, 1 Selects Table B
0x30100 AIL_PHY_CI_LUT_A_Configuration_Register rw — (1 of 8, stride 4)
  [13] smpl_last — Indicates this is the last AXC Contgainer Group to be used when set. All group entries after this one are ignored.
  [12:11] smpl_type — Defines the sample type for AxC Container Group
  [10:6] smpl_offset — Defines the number of unused bits (gap) preceeding this container group. This value must be an even number from 0x0 to 0x1e
  [5:0] smpl_count — Defines the number of consecutive AxC Containers in the AxC Container Group
0x30140 AIL_PHY_CI_LUT_B_Configuration_Register rw — (1 of 8, stride 4)
  fields as AIL_PHY_CI_LUT_A_Configuration_Register
0x30180 AIL_PHY_CO_LUT_A_Configuration_Register rw — (1 of 8, stride 4)
  fields as AIL_PHY_CI_LUT_A_Configuration_Register
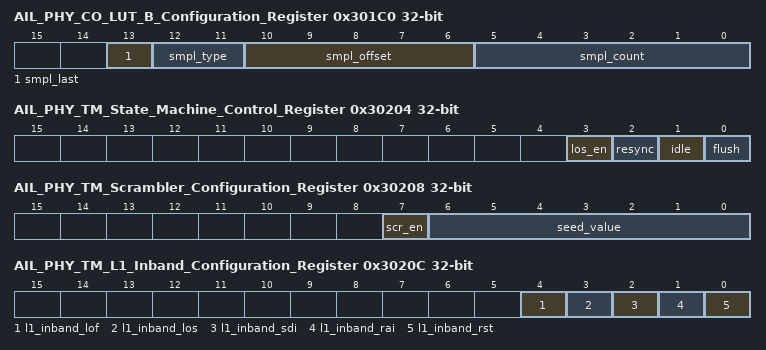
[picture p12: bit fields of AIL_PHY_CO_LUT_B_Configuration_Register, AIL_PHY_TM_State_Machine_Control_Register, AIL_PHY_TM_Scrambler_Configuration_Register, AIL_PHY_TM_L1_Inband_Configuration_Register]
0x301C0 AIL_PHY_CO_LUT_B_Configuration_Register rw — (1 of 8, stride 4)
  fields as AIL_PHY_CI_LUT_A_Configuration_Register
0x30200 AIL_PHY_TM_Configuration_Register rw — (1 of 1, stride 0)
  [0] en — The Transmit Enable Bit allows the TM block transmit state machine to operate
0x30204 AIL_PHY_TM_State_Machine_Control_Register rw — (1 of 1, stride 0)
  [3] los_en — When set, Loss of Signal from the RM to cause the TM state machine to transition to the OFF state.
  [2] resync — Forces the Frame Sync state machine to transition from the FRAME_SYNC state to the RESYNC state and remain in the RESYNC state until the bit is cleared. If the state machine is in either the OFF state or the IDLE state, this bit is ignored until the state
  [1] idle — Forces the Frame Sync state machine to transition from either the FRAME_SYNC or RESYNC states to the IDLE state and remain in the IDLE state until the bit is cleared. If the state machine is in the OFF state, this bit is ignored until the state machine
  [0] flush — Instructs the TM link to flush the FIFO and force a TM Fail condition on the link. When set high, the State machine is forced into the RE_SYNC state
0x30208 AIL_PHY_TM_Scrambler_Configuration_Register rw — (1 of 1, stride 0)
  [7] scr_en — Enables the scrambler for operation in the transmit data path.
  [6:0] seed_value — The seed value is used to initialize the transmit scrambler circuit
0x3020C AIL_PHY_TM_L1_Inband_Configuration_Register rw — (1 of 1, stride 0)
  [4] l1_inband_lof — LOF (see CPRI spec for usage)
  [3] l1_inband_los — LOS (see CPRI spec for usage)
  [2] l1_inband_sdi — SDI (see CPRI spec for usage)
  [1] l1_inband_rai — RAI (see CPRI spec for usage)
  [0] l1_inband_rst — RST (see CPRI spec for usage)
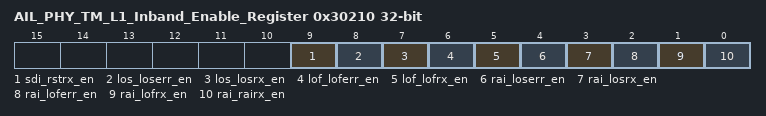
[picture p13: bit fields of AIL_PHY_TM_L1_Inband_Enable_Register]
0x30210 AIL_PHY_TM_L1_Inband_Enable_Register rw — (1 of 1, stride 0)
  [9] sdi_rstrx_en — Enables l1_inband SDI active upon rstrx signal from RM
  [8] los_loserr_en — Enables l1_inband LOS active upon loserr signal from RM
  [7] los_losrx_en — Enables l1_inband LOS active upon losrx signal from RM
  [6] lof_loferr_en — Enables l1_inband LOF active upon loferr signal from RM
  [5] lof_lofrx_en — Enables l1_inband LOF active upon lofrx signal from RM
  [4] rai_loserr_en — Enables l1_inband RAI active upon loserr signal from RM
  [3] rai_losrx_en — Enables l1_inband RAI active upon losrx signal from RM
  [2] rai_loferr_en — Enables l1_inband RAI active upon loferr signal from RM
  [1] rai_lofrx_en — Enables l1_inband RAI active upon lofrx signal from RM
  [0] rai_rairx_en — Enables l1_inband RAI active upon rairx signal from RM
0x30214 AIL_PHY_TM_Los_Error_Register rw — (1 of 1, stride 0)
  [2:0] link_loserr — RM Link LOSERR Select
0x30218 AIL_PHY_TM_Lof_Error_Register rw — (1 of 1, stride 0)
  [2:0] link_loferr — RM Link LOFERR Select
0x3021C AIL_PHY_TM_Los_Rx_Register rw — (1 of 1, stride 0)
  [2:0] link_losrx — RM Link LOSRx Select
0x30220 AIL_PHY_TM_Lof_Rx_Register rw — (1 of 1, stride 0)
  [2:0] link_lofrx — RM Link LOFRx Select
0x30224 AIL_PHY_TM_RAI_Rx_Register rw — (1 of 1, stride 0)
  [2:0] link_rairx — RM Link RAIRx Select
0x30228 AIL_PHY_TM_RST_Rx_Register rw — (1 of 1, stride 0)
  [2:0] link_rstrx — RM Link RSTRx Select
0x3022C AIL_PHY_TM_CPRI_HFN_Status_Register — (1 of 1, stride 0)
  [7:0] hfn — Synchronization field. The Hyperframe number of the currently transmitting frame
0x30230 AIL_PHY_TM_CPRI_Pointer_P_Configuration rw — (1 of 1, stride 0)
  [7:0] ptr_p — L1 inband field. Pointer P value which is inserted into the CPRI Egress link.
0x30234 AIL_PHY_TM_CPRI_Startup_Configurtaion_Register rw — (1 of 1, stride 0)
  [7:0] startup — L1 inband field. Startup value which is inserted into the CPRI Egress link.
0x30238 AIL_PHY_TM_CPRI_Version_Configuration_Register rw — (1 of 1, stride 0)
  [7:0] prot_vers — L1 inband field. Protocol version value which is inserted into the CPRI Egress link.
